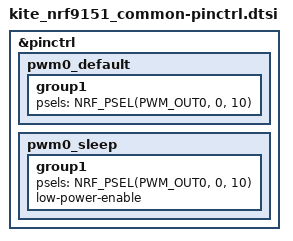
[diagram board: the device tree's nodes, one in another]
/*
 * Copyright (c) 2023 Elektronikutvecklingsbyrån EUB AB
 * SPDX-License-Identifier: Apache-2.0
 */

&pinctrl {

	pwm0_default: pwm0_default {
		group1 {
			psels = <NRF_PSEL(PWM_OUT0, 0, 10)>;
		};
	};

	pwm0_sleep: pwm0_sleep {
		group1 {
			psels = <NRF_PSEL(PWM_OUT0, 0, 10)>;
			low-power-enable;
		};
	};

};
